# FM33LC0XX register map
File version: 1.0
CPU: SC123, little endian, no MPU, no FPU, 3 interrupt priority bits
Registers are 32-bit, read-write, reset 0x0 unless marked. A register's access mark holds for its fields unless they carry their own. Offsets are from the block's base; [hi:lo] are bit positions; {n}, {i} and the like mark numbered series; 'fields as' and 'values as' point back to an identical list.

## GPTIM0 — GPTIM0 module information
Base 0x40013800
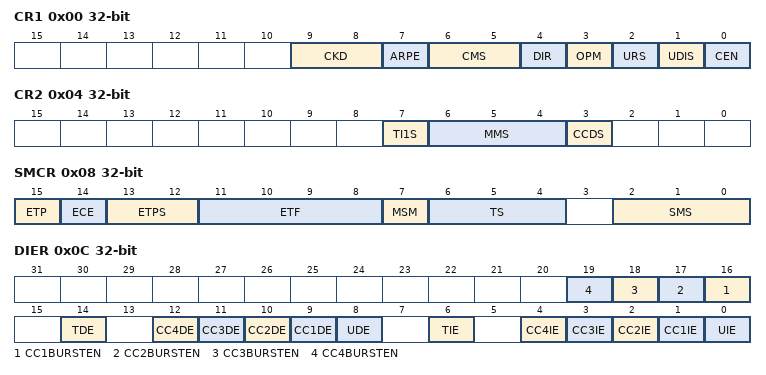
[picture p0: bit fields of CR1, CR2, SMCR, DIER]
0x00 CR1 — GPTIM0 Control Register1
  [9:8] CKD — CKD field description
  [7] ARPE — ARPE field description
  [6:5] CMS — CMS field description
  [4] DIR — DIR field description
  [3] OPM — OPM field description
  [2] URS — URS field description
  [1] UDIS — UDIS field description
  [0] CEN — CEN field description
0x04 CR2 — GPTIM0 Control Register2
  [7] TI1S — TI1S field description
  [6:4] MMS — MMS field description
  [3] CCDS — CCDS field description
0x08 SMCR — GPTIM0 Slave Mode Control Register
  [15] ETP — ETP field description
  [14] ECE — ECE field description
  [13:12] ETPS — ETPS field description
  [11:8] ETF — ETF field description
  [7] MSM — MSM field description
  [6:4] TS — TS field description
  [2:0] SMS — SMS field description
0x0C DIER — GPTIM0 DMA and Interrupt Enable Register
  [n+15] CC{n}BURSTEN (n=1..4) — CC{n}BURSTEN field description
  [14] TDE — TDE field description
  [n+8] CC{n}DE (n=1..4) — CC{n}DE field description
  [8] UDE — UDE field description
  [6] TIE — TIE field description
  [n] CC{n}IE (n=1..4) — CC{n}IE field description
  [0] UIE — UIE field description
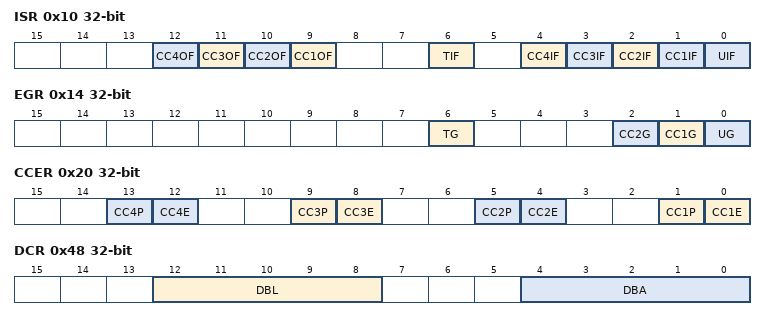
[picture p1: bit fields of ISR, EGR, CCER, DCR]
0x10 ISR — GPTIM0 Interrupt Status Register
  [n+8] CC{n}OF (n=1..4) — CC{n}OF field description
  [6] TIF — TIF field description
  [n] CC{n}IF (n=1..4) — CC{n}IF field description
  [0] UIF — UIF field description
0x14 EGR — GPTIM0 Event Generation Register
  [6] TG wo — TG field description
  [2] CC2G wo — CC2G field description
  [1] CC1G wo — CC1G field description
  [0] UG wo — UG field description
0x18 CCMR1 — GPTIM0 Capture/Compare Mode Register1
  [15] OC2CE — OC2CE field description
  [14:12] OC2M — OC2M field description
  [15:12] IC2F — IC2F field description
  [11] OC2PE — OC2PE field description
  [10] OC2FE — OC2FE field description
  [11:10] IC2PSC — IC2PSC field description
  [9:8] CC2S — CC2S field description
  [9:8] CC2S — CC2S field description
  [7] OC1CE — OC1CE field description
  [6:4] OC1M — OC1M field description
  [7:4] IC1F — IC1F field description
  [3] OC1PE — OC1PE field description
  [2] OC1FE — OC1FE field description
  [3:2] IC1PSC — IC1PSC field description
  [1:0] CC1S — CC1S field description
  [1:0] CC1S — CC1S field description
0x18 CCMR1 — GPTIM0 Capture/Compare Mode Register1
  fields as CCMR1
0x1C CCMR2 — GPTIM0 Capture/Compare Mode Register2
  [15] OC4CE — OC4CE field description
  [14:12] OC4M — OC4M field description
  [15:12] IC4F — IC4F field description
  [11] OC4PE — OC4PE field description
  [10] OC4FE — OC4FE field description
  [9:8] CC4S — CC4S field description
  [9:8] CC4S — CC4S field description
  [7] OC3CE — OC3CE field description
  [6:4] OC3M — OC3M field description
  [7:4] IC3F — IC3F field description
  [3] OC3PE — OC3PE field description
  [2] OC3FE — OC3FE field description
  [3:2] IC3PSC — IC3PSC field description
  [1:0] CC3S — CC3S field description
  [1:0] CC3S — CC3S field description
0x1C CCMR2 — GPTIM0 Capture/Compare Mode Register2
  fields as CCMR2
0x20 CCER — GPTIM0 Capture/Compare Enable Register
  [4n-3] CC{n}P (n=1..4) — CC{n}P field description
  [4n-4] CC{n}E (n=1..4) — CC{n}E field description
0x24 CNT — GPTIM0 Counter Register
  [15:0] CNT — CNT field description
0x28 PSC — GPTIM0 Prescaler Register
  [15:0] PSC — PSC field description
0x2C ARR — GPTIM0 Auto-Reload Register
  [15:0] ARR — ARR field description
{0x30+4i} CCR{i} (i=1..4) — GPTIM0 Capture/Compare Register{i}
  [15:0] CCR{i} — CCR{i} field description
0x48 DCR — GPTIM0 DMA Control Register
  [12:8] DBL — DBL field description
  [4:0] DBA — DBA field description
0x4C DMAR — GPTIM0 DMA access Register
  [15:0] DMAR — DMAR field description
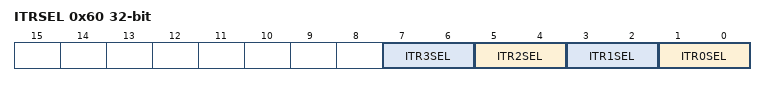
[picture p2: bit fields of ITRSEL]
0x60 ITRSEL — GPTIM0 Internal Trigger Select Register
  [2n+1:2n] ITR{n}SEL (n=0..3) — ITR{n}SEL field description
